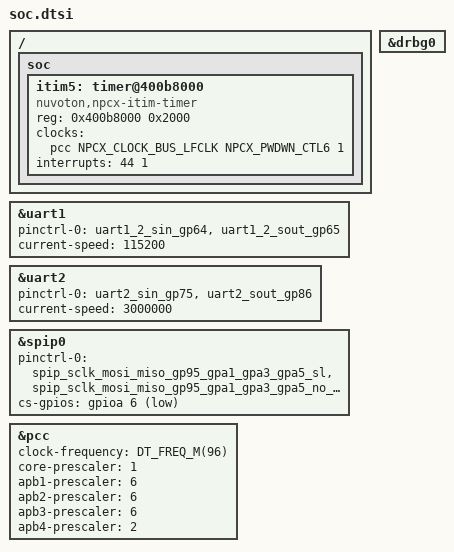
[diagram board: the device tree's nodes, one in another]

/* Copyright 2025 The ChromiumOS Authors.
 * Use of this source code is governed by a BSD-style license that can be
 * found in the LICENSE file.
 */
#include <cros/nuvoton/npcx9_cros.dtsi>
#include <nuvoton/npcx/npcx9/npcx9-pinctrl.dtsi>

/ {
       soc {
              itim5: timer@400b8000 {
                     compatible = "nuvoton,npcx-itim-timer";
                     reg = <0x400b8000 0x2000>;
                     clocks = <&pcc NPCX_CLOCK_BUS_LFCLK NPCX_PWDWN_CTL6 1>;
                     interrupts = <44 1>; /* Event timer interrupt */
              };
       };
};

/* DRBG: Deterministic Random Bit Generator */
&drbg0 {
	status = "okay";
};

/* UART1: Servo UART (console) */
&uart1 {
      /* Use UART1_SL2 ie. PIN64.65 */
       pinctrl-0 = <&uart1_2_sin_gp64
                    &uart1_2_sout_gp65>;
       pinctrl-names = "default";
       current-speed = <115200>;
};

/* UART2: AP UART (Host Commands and MKBP) */
&uart2 {
       pinctrl-0 = <&uart2_sin_gp75
                        &uart2_sout_gp86>;
       pinctrl-names = "default";
       current-speed = <3000000>;
};

/*
 * SPI0: communication with the fingerprint sensor
 */
&spip0 {
	pinctrl-0 = <&spip_sclk_mosi_miso_gp95_gpa1_gpa3_gpa5_sl
		     &spip_sclk_mosi_miso_gp95_gpa1_gpa3_gpa5_no_spip_inv>;
	pinctrl-names = "default";
	cs-gpios = <&gpioa 6 GPIO_ACTIVE_LOW>;
	status = "okay";
};

/*
 * PCC: increase core/APB clock to 96 MHz
 */
&pcc {
	clock-frequency = <DT_FREQ_M(96)>; /* OFMCLK runs at 96 MHz */
	core-prescaler = <1>; /* CORE_CLK runs at 96 MHz */
	apb1-prescaler = <6>; /* APB1_CLK runs at 16 MHz */
	apb2-prescaler = <6>; /* APB2_CLK runs at 16 MHz */
	apb3-prescaler = <6>; /* APB3_CLK runs at 16 MHz */
	/*
	 * APB4_CLK runs at 48 MHz, required to support
	 * UART2 Baudrate=3 MHz
	 */
	apb4-prescaler = <2>;
};
